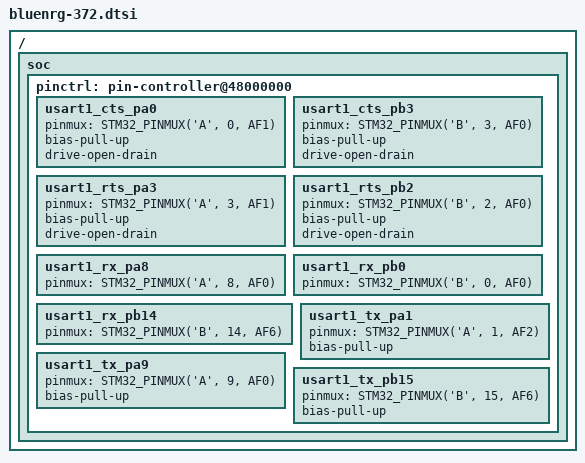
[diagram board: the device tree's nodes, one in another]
/*
 * Copyright (c) 2024 STMicroelectronics
 * SPDX-License-Identifier: Apache-2.0
 */

#include <zephyr/dt-bindings/pinctrl/stm32-pinctrl.h>

/ {
	soc {
		pinctrl: pin-controller@48000000 {

			/omit-if-no-ref/ usart1_cts_pa0: usart1_cts_pa0 {
				pinmux = <STM32_PINMUX('A', 0, AF1)>;
				bias-pull-up;
				drive-open-drain;
			};

			/omit-if-no-ref/ usart1_cts_pb3: usart1_cts_pb3 {
				pinmux = <STM32_PINMUX('B', 3, AF0)>;
				bias-pull-up;
				drive-open-drain;
			};

			/omit-if-no-ref/ usart1_rts_pa3: usart1_rts_pa3 {
				pinmux = <STM32_PINMUX('A', 3, AF1)>;
				bias-pull-up;
				drive-open-drain;
			};

			/omit-if-no-ref/ usart1_rts_pb2: usart1_rts_pb2 {
				pinmux = <STM32_PINMUX('B', 2, AF0)>;
				bias-pull-up;
				drive-open-drain;
			};

			/omit-if-no-ref/ usart1_rx_pa8: usart1_rx_pa8 {
				pinmux = <STM32_PINMUX('A', 8, AF0)>;
			};

			/omit-if-no-ref/ usart1_rx_pb0: usart1_rx_pb0 {
				pinmux = <STM32_PINMUX('B', 0, AF0)>;
			};

			/omit-if-no-ref/ usart1_rx_pb14: usart1_rx_pb14 {
				pinmux = <STM32_PINMUX('B', 14, AF6)>;
			};

			/omit-if-no-ref/ usart1_tx_pa1: usart1_tx_pa1 {
				pinmux = <STM32_PINMUX('A', 1, AF2)>;
				bias-pull-up;
			};

			/omit-if-no-ref/ usart1_tx_pa9: usart1_tx_pa9 {
				pinmux = <STM32_PINMUX('A', 9, AF0)>;
				bias-pull-up;
			};

			/omit-if-no-ref/ usart1_tx_pb15: usart1_tx_pb15 {
				pinmux = <STM32_PINMUX('B', 15, AF6)>;
				bias-pull-up;
			};
		};
	};
};
